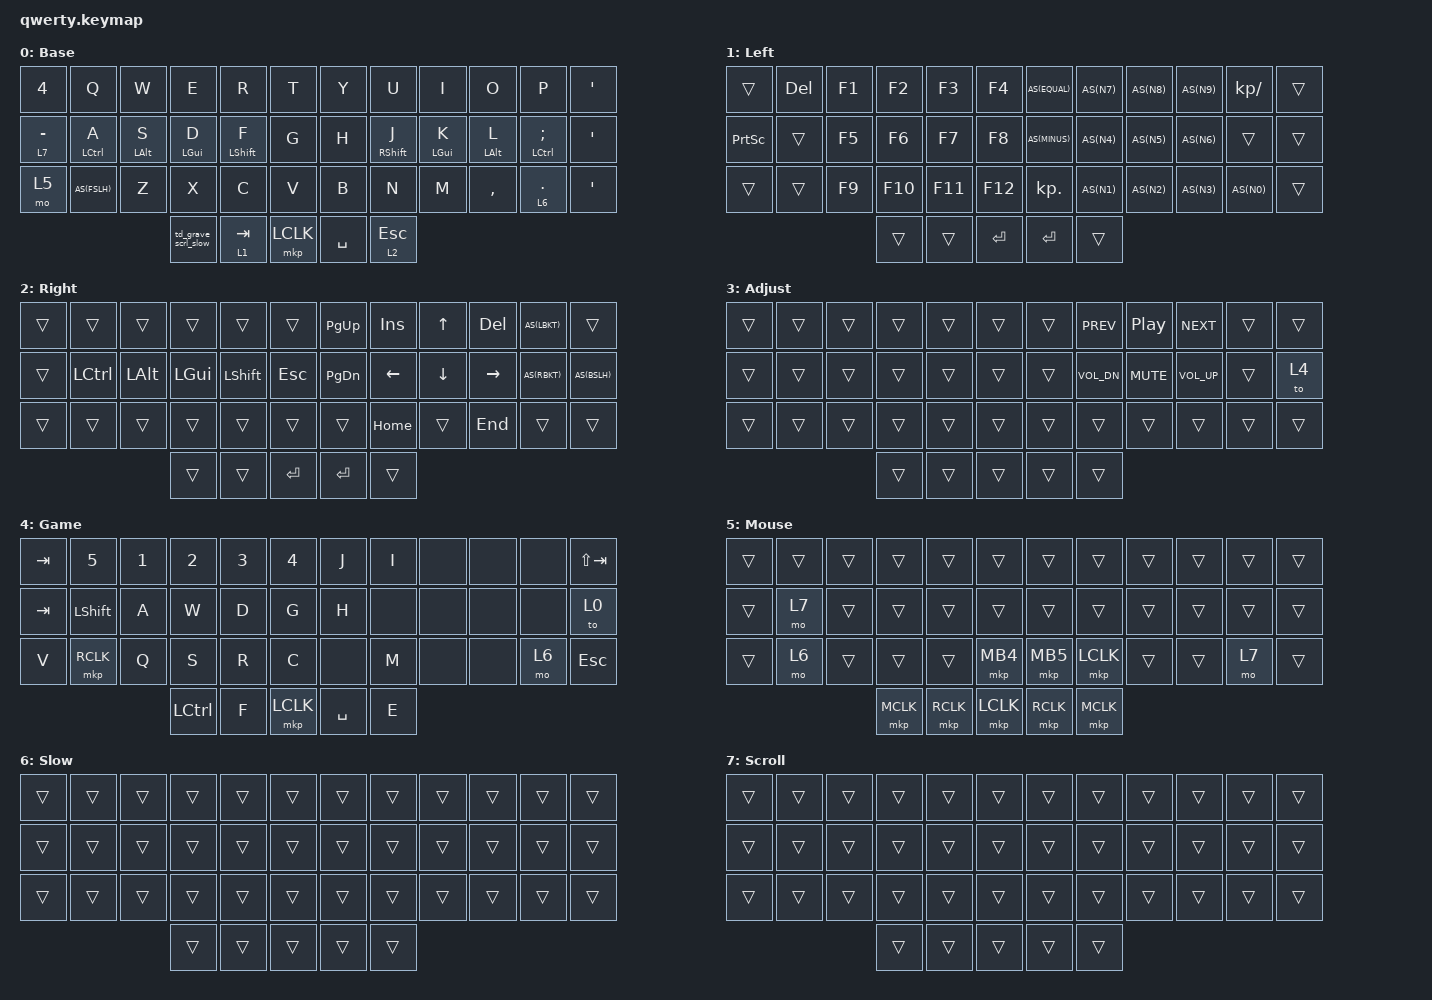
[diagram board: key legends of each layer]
/* upstream bindings and behaviors */
#include <behaviors.dtsi>
#include <dt-bindings/zmk/bt.h>
#include <dt-bindings/zmk/keys.h>
#include <dt-bindings/zmk/mouse.h>
#include <dt-bindings/zmk/outputs.h>
#include <behaviors/mouse_keys.dtsi>
#include <dt-bindings/zmk/ext_power.h>

/* local overlays */
#include "macros.dtsi"
#include "behaviors.dtsi"
#include "combos.dtsi"


/* --- KEYMAP CONFIG --- */
// ╭──────┬──────┬──────┬──────┬──────┬──────╮  ╭──────┬──────┬──────┬──────┬──────┬──────╮
//    00     01     02     03    04      05        06     07     08     09     10     11
// ├──────┼──────┼──────┼──────┼──────┼──────┤  ├──────┼──────┼──────┼──────┼──────┼──────┤
//    12     13     14     15    16      17        18     19     20     21     22     23
// ├──────┼──────┼──────┼──────┼──────┼──────┤  ├──────┼──────┼──────┼──────┼──────┼──────┤
//    24     25     26     27    28      29        30     31     32     33     34     35
// ╰──────┴──────┴──────┼──────┼──────┼──────┤  ├──────┼──────┼──────┴──────┴──────┴──────╯
//                         36     37     38        39     40
//                      ╰──────┴──────┴──────╯  ╰──────┴──────╯
// #define BASE    0
// #define LEFT    1
// #define RIGHT   2
// #define ADJUST  3
// #define GAME    4
// #define MOUSE   5
// #define SLOW    6
// #define SCROLL  7

/ {
    keymap {
        compatible = "zmk,keymap";
        base_layer {
            display-name = "Base";
            bindings = <
// ╭───────────────┬────────────────┬────────────────┬─────────────────┬─────────────────┬──────╮  ╭──────┬──────────────────┬──────────────────┬─────────────────┬────────────────────────┬─────────────╮
    &kp N4          &kp Q            &kp W            &kp E             &kp R             &kp T     &kp Y  &kp U              &kp I              &kp O             &kp P                     &kp SQT
// ├───────────────┼────────────────┼────────────────┼─────────────────┼─────────────────┼──────┤  ├──────┼──────────────────┼──────────────────┼─────────────────┼────────────────────────┼─────────────┤
    &lt 7 MINUS     &ht_left LCTRL A  &ht_left LALT S  &ht_left LGUI D  &ht_left LSHFT F  &kp G     &kp H  &ht_right RSHFT J  &ht_right LGUI K  &ht_right LALT L   &ht_right LCTRL SEMICOLON &kp SQT
// ├───────────────┼────────────────┼────────────────┼─────────────────┼─────────────────┼──────┤  ├──────┼──────────────────┼──────────────────┼─────────────────┼────────────────────────┼─────────────┤
    &mo 5           AS(FSLH)         &kp Z            &kp X             &kp C             &kp V     &kp B  &kp N              &kp M              &kp COMMA         &lt 6 DOT                 &kp SQT
// ╰───────────────┴────────────────┴────────────────┼─────────────────┼─────────────────┼──────┤  ├──────┼──────────────────┼──────────────────┴─────────────────┴────────────────────────┴─────────────╯
                                                      &td_grave_scrl_slow &lt 1 TAB  &mkp LCLK      &kp SPACE  &lt 2 ESC
                                                 //  ╰──────────────────┴─────────┴──────╯         ╰──────────┴──────────────╯
            >;
        };

        left_layer {
            display-name = "Left";
            bindings = <
&trans    &kp DEL    &kp F1    &kp F2    &kp F3    &kp F4     /**/  AS(EQUAL)     AS(N7)    AS(N8)    AS(N9)    &kp KP_SLASH    &trans
&kp PSCRN &trans     &kp F5    &kp F6    &kp F7    &kp F8     /**/  AS(MINUS)     AS(N4)    AS(N5)    AS(N6)    &trans          &trans
&trans    &trans     &kp F9    &kp F10   &kp F11   &kp F12    /**/  &kp KP_DOT    AS(N1)    AS(N2)    AS(N3)    AS(N0)          &trans
                               &trans    &trans    &kp ENTER  /**/  &kp ENTER     &trans

            >;
        };

        right_layer {
            display-name = "Right";
            bindings = <
&trans    &trans       &trans      &trans      &trans       &trans     /**/  &kp PG_UP    &kp INS     &kp UP      &kp DEL      AS(LBKT)    &trans
&trans    &kp LCTRL    &kp LALT    &kp LGUI    &kp LSHFT    &kp ESC    /**/  &kp PG_DN    &kp LEFT_ARROW    &kp DOWN    &kp RIGHT_ARROW    AS(RBKT)    AS(BSLH)
&trans    &trans       &trans      &trans      &trans       &trans     /**/  &trans       &kp HOME    &trans      &kp END      &trans      &trans
                                   &trans      &trans       &kp ENTER  /**/  &kp ENTER       &trans
            >;
        };

        adjust_tri_layer {
            display-name = "Adjust";
            bindings = <
&trans    &trans    &trans    &trans    &trans    &trans  /**/  &trans    &kp C_PREV    &kp C_PP    &kp C_NEXT    &trans    &trans
&trans    &trans    &trans    &trans    &trans    &trans  /**/  &trans    &kp C_VOL_DN    &kp C_MUTE    &kp C_VOL_UP   &trans    &to 4
&trans    &trans    &trans    &trans    &trans    &trans  /**/  &trans    &trans    &trans    &trans    &trans    &trans
                              &trans    &trans    &trans  /**/  &trans    &trans
            >;
        };

        game_layer {
            display-name = "Game";
            bindings = <
&kp TAB   &kp N5       &kp N1   &kp N2    &kp N3   &kp N4     /**/  &kp J     &kp I    &none    &none    &none    &kp LS(TAB)
&kp TAB   &kp LSHFT    &kp A    &kp W     &kp D    &kp G      /**/  &kp H     &none    &none    &none    &none    &to 0
&kp V     &mkp RCLK    &kp Q    &kp S     &kp R    &kp C      /**/  &none     &kp M    &none    &none    &mo 6    &kp ESC
                                &kp LCTRL &kp F    &mkp LCLK  /**/  &kp SPACE &kp E
            >;
        };

        mouse_layer {
            display-name = "Mouse";
            bindings = <
&trans    &trans   &trans    &trans    &trans    &trans      &trans    /**/  &trans    &trans    &trans    &trans    &trans
&trans    &mo 7    &trans    &trans    &trans    &trans      &trans    /**/  &trans    &trans    &trans    &trans    &trans
&trans    &mo 6    &trans    &trans    &trans    &mkp MB4    &mkp MB5  /**/  &mkp LCLK    &trans    &trans    &mo 7    &trans
                                    &mkp MCLK    &mkp RCLK   &mkp LCLK /**/  &mkp RCLK    &mkp MCLK
            >;
        };

        slow_layer {
            display-name = "Slow";
            bindings = <
&trans    &trans    &trans    &trans    &trans    &trans  /**/  &trans    &trans    &trans    &trans    &trans    &trans
&trans    &trans    &trans    &trans    &trans    &trans  /**/  &trans    &trans    &trans    &trans    &trans    &trans
&trans    &trans    &trans    &trans    &trans    &trans  /**/  &trans    &trans    &trans    &trans    &trans    &trans
                              &trans    &trans    &trans  /**/  &trans    &trans
            >;
        };

        scroll_layer {
            display-name = "Scroll";
            bindings = <
&trans    &trans    &trans    &trans    &trans    &trans  /**/  &trans    &trans    &trans    &trans    &trans    &trans
&trans    &trans    &trans    &trans    &trans    &trans  /**/  &trans    &trans    &trans    &trans    &trans    &trans
&trans    &trans    &trans    &trans    &trans    &trans  /**/  &trans    &trans    &trans    &trans    &trans    &trans
                              &trans    &trans    &trans  /**/  &trans    &trans
            >;
        };

        conditional_layers {
            compatible = "zmk,conditional-layers";

            tri_layer {
                if-layers = <1 2>;
                then-layer = <3>;
            };
        };
    };
};
